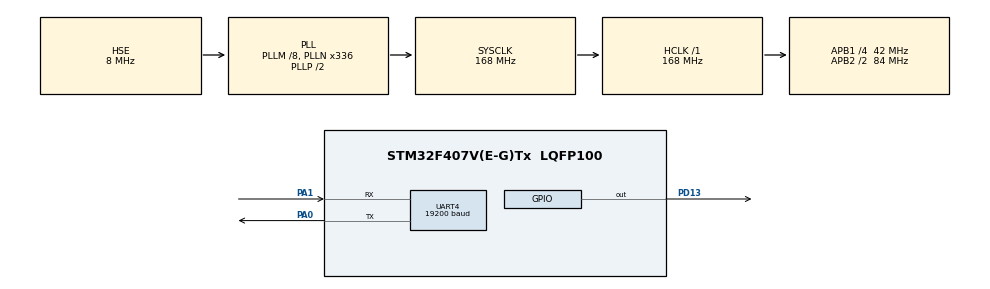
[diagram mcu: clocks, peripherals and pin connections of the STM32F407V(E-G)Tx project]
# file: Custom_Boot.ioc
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Mcu.Family=STM32F4
Mcu.Name=STM32F407V(E-G)Tx
Mcu.Package=LQFP100
NVIC.PriorityGroup=NVIC_PRIORITYGROUP_4
PA0-WKUP.Mode=Asynchronous
PA0-WKUP.Signal=UART4_TX
PA1.Mode=Asynchronous
PA1.Signal=UART4_RX
PD13.Signal=GPIO_Output
PH0-OSC_IN.Mode=HSE-External-Oscillator
PH0-OSC_IN.Signal=RCC_OSC_IN
PH1-OSC_OUT.Mode=HSE-External-Oscillator
PH1-OSC_OUT.Signal=RCC_OSC_OUT
ProjectManager.HeapSize=0x200
ProjectManager.StackSize=0x400
ProjectManager.TargetToolchain=STM32CubeIDE
RCC.48MHZClocksFreq_Value=84000000
RCC.AHBFreq_Value=168000000
RCC.APB1CLKDivider=RCC_HCLK_DIV4
RCC.APB1Freq_Value=42000000
RCC.APB1TimFreq_Value=84000000
RCC.APB2CLKDivider=RCC_HCLK_DIV2
RCC.APB2Freq_Value=84000000
RCC.APB2TimFreq_Value=168000000
RCC.CortexFreq_Value=168000000
RCC.HCLKFreq_Value=168000000
RCC.HSE_VALUE=8000000
RCC.HSI_VALUE=16000000
RCC.LSE_VALUE=32768
RCC.PLLM=8
RCC.PLLN=336
RCC.PLLSourceVirtual=RCC_PLLSOURCE_HSE
RCC.SYSCLKFreq_VALUE=168000000
RCC.SYSCLKSource=RCC_SYSCLKSOURCE_PLLCLK
RCC.VCOOutputFreq_Value=336000000
UART4.BaudRate=19200
UART4.VirtualMode=Asynchronous
board=custom

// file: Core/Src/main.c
/* USER CODE BEGIN Header */
/**
  ******************************************************************************
  * @file           : main.c
  * @brief          : Main program body
  ******************************************************************************
  * @attention
  *
  * Copyright (c) 2026 STMicroelectronics.
  * All rights reserved.
  *
  * This software is licensed under terms that can be found in the LICENSE file
  * in the root directory of this software component.
  * If no LICENSE file comes with this software, it is provided AS-IS.
  *
  ******************************************************************************
  */
/* USER CODE END Header */
#include "main.h"

/* USER CODE BEGIN Includes */
#include "bl_jump.h"
#include "bl_ota.h"
#include "ota_image.h"
/* USER CODE END Includes */

UART_HandleTypeDef huart4;

void SystemClock_Config(void);
static void MX_GPIO_Init(void);
static void MX_UART4_Init(void);

/* USER CODE BEGIN 0 */

static uint32_t mem_base = 0;  // used with external or dual flash
static uint32_t mem_cursor = 0;
static uint32_t ota_image_total_size = 16;  // expected OTA Header size

void ota_mem_set_total_size(uint32_t size)
{
    ota_image_total_size = size;
}

int ota_read_mem(uint8_t *buf, uint32_t len)
{
    if (mem_cursor + len > ota_image_total_size)
        return -1;

    memcpy(buf, &ota_image_bin[mem_base + mem_cursor], len);  // this function should be replaced accordingly

    mem_cursor += len;
    return 0;
}

/* USER CODE END 0 */

int main(void)
{

  /* MCU Configuration--------------------------------------------------------*/

  /* Reset of all peripherals, Initializes the Flash interface and the Systick. */
  HAL_Init();

  /* Configure the system clock */
  SystemClock_Config();

  /* Initialize all configured peripherals */
  MX_GPIO_Init();
  MX_UART4_Init();
  /* USER CODE BEGIN 2 */
  HAL_Delay(100);
  RCC->AHB1ENR |= RCC_AHB1ENR_GPIODEN;          // Active l'horloge de GPIOD
  GPIOD->MODER = (GPIOD->MODER & ~(3U << (13*2))) | (1U << (13*2)); // PD13 en sortie
  GPIOD->ODR |= (1U << 13);

  // TEST FLASH//

  // TEST FLASH//

  HAL_UART_Transmit(&huart4, (uint8_t *)"Inside Bootloader!!\r\n", 21, 100);

  if (check_ota_request() != 0)//check_ota_request() == 0
  {
	  HAL_UART_Transmit(&huart4, (uint8_t *)"Performing OTA...\n", 18, 100);

	  ota_stream_t stream =
	  {
	      .read = ota_read_mem,
	      .set_total_size = ota_mem_set_total_size
	  };

	  bl_ota_ctx_t ctx;
	 if (bl_ota_run(&ctx, &stream) != 0)
	 {
		 HAL_UART_Transmit(&huart4, (uint8_t *)"OTA Failed...\n", 14, 100);
		  while (1)
		  {
			  HAL_GPIO_TogglePin(GPIOD, GPIO_PIN_12);
			  HAL_Delay(250);
		  }
	 }
	 else {
		 HAL_UART_Transmit(&huart4, (uint8_t *)"OTA Flashed Successfully, Jumping to app...\n", 44, 100);
	 }

  }
  int err = bootloader_is_app_valid();
  if (err != 0)
  {
	  HAL_UART_Transmit(&huart4, (uint8_t *)"Failed to Jump!! ", 17, 100);
	  switch (err){
	  case 1:
		  HAL_UART_Transmit(&huart4, (uint8_t *)"MAGIC ERROR!!\r\n", 15, 100);
		  break;

	  case 2:
		  HAL_UART_Transmit(&huart4, (uint8_t *)"RESET ERROR!!\r\n", 15, 100);
		  break;

	  case 3:
		  HAL_UART_Transmit(&huart4, (uint8_t *)"SIZE ERROR!!\r\n", 14, 100);
		  break;

	  case 4:
		  HAL_UART_Transmit(&huart4, (uint8_t *)"CRC ERROR!!\r\n", 13, 100);
		  break;

	  default:
		  HAL_UART_Transmit(&huart4, (uint8_t *)"ERROR!!\r\n", 9, 100);
		  break;
	  }
  }

  JumpToApplication(); // Jump to the application
  /* USER CODE END 2 */

  /* Infinite loop */
  while (1)
  {

  }
}

void SystemClock_Config(void)
{
  RCC_OscInitTypeDef RCC_OscInitStruct = {0};
  RCC_ClkInitTypeDef RCC_ClkInitStruct = {0};

  /** Configure the main internal regulator output voltage
  */
  __HAL_RCC_PWR_CLK_ENABLE();
  __HAL_PWR_VOLTAGESCALING_CONFIG(PWR_REGULATOR_VOLTAGE_SCALE1);

  /** Initializes the RCC Oscillators according to the specified parameters
  * in the RCC_OscInitTypeDef structure.
  */
  RCC_OscInitStruct.OscillatorType = RCC_OSCILLATORTYPE_HSE;
  RCC_OscInitStruct.HSEState = RCC_HSE_ON;
  RCC_OscInitStruct.PLL.PLLState = RCC_PLL_ON;
  RCC_OscInitStruct.PLL.PLLSource = RCC_PLLSOURCE_HSE;
  RCC_OscInitStruct.PLL.PLLM = 8;
  RCC_OscInitStruct.PLL.PLLN = 336;
  RCC_OscInitStruct.PLL.PLLP = RCC_PLLP_DIV2;
  RCC_OscInitStruct.PLL.PLLQ = 4;
  if (HAL_RCC_OscConfig(&RCC_OscInitStruct) != HAL_OK)
  {
    Error_Handler();
  }

  /** Initializes the CPU, AHB and APB buses clocks
  */
  RCC_ClkInitStruct.ClockType = RCC_CLOCKTYPE_HCLK|RCC_CLOCKTYPE_SYSCLK
                              |RCC_CLOCKTYPE_PCLK1|RCC_CLOCKTYPE_PCLK2;
  RCC_ClkInitStruct.SYSCLKSource = RCC_SYSCLKSOURCE_PLLCLK;
  RCC_ClkInitStruct.AHBCLKDivider = RCC_SYSCLK_DIV1;
  RCC_ClkInitStruct.APB1CLKDivider = RCC_HCLK_DIV4;
  RCC_ClkInitStruct.APB2CLKDivider = RCC_HCLK_DIV2;

  if (HAL_RCC_ClockConfig(&RCC_ClkInitStruct, FLASH_LATENCY_5) != HAL_OK)
  {
    Error_Handler();
  }
}

static void MX_UART4_Init(void)
{

  huart4.Instance = UART4;
  huart4.Init.BaudRate = 19200;
  huart4.Init.WordLength = UART_WORDLENGTH_8B;
  huart4.Init.StopBits = UART_STOPBITS_1;
  huart4.Init.Parity = UART_PARITY_NONE;
  huart4.Init.Mode = UART_MODE_TX_RX;
  huart4.Init.HwFlowCtl = UART_HWCONTROL_NONE;
  huart4.Init.OverSampling = UART_OVERSAMPLING_16;
  if (HAL_UART_Init(&huart4) != HAL_OK)
  {
    Error_Handler();
  }

}

static void MX_GPIO_Init(void)
{
  GPIO_InitTypeDef GPIO_InitStruct = {0};

  /* GPIO Ports Clock Enable */
  __HAL_RCC_GPIOH_CLK_ENABLE();
  __HAL_RCC_GPIOA_CLK_ENABLE();
  __HAL_RCC_GPIOD_CLK_ENABLE();

  /*Configure GPIO pin Output Level */
  HAL_GPIO_WritePin(GPIOD, GPIO_PIN_13, GPIO_PIN_RESET);

  /*Configure GPIO pin : PD13 */
  GPIO_InitStruct.Pin = GPIO_PIN_13;
  GPIO_InitStruct.Mode = GPIO_MODE_OUTPUT_PP;
  GPIO_InitStruct.Pull = GPIO_NOPULL;
  GPIO_InitStruct.Speed = GPIO_SPEED_FREQ_LOW;
  HAL_GPIO_Init(GPIOD, &GPIO_InitStruct);

  /* USER CODE BEGIN MX_GPIO_Init_2 */
  /* UART4 TX PA0 */
  GPIO_InitStruct.Pin = GPIO_PIN_0;
  GPIO_InitStruct.Mode = GPIO_MODE_AF_PP;
  GPIO_InitStruct.Pull = GPIO_NOPULL;
  GPIO_InitStruct.Speed = GPIO_SPEED_FREQ_VERY_HIGH;
  GPIO_InitStruct.Alternate = GPIO_AF8_UART4;
  HAL_GPIO_Init(GPIOA, &GPIO_InitStruct);

  /* UART4 RX PA1 */
  GPIO_InitStruct.Pin = GPIO_PIN_1;
  GPIO_InitStruct.Alternate = GPIO_AF8_UART4;
  HAL_GPIO_Init(GPIOA, &GPIO_InitStruct);

  /* USER CODE END MX_GPIO_Init_2 */
}

void Error_Handler(void)
{
  __disable_irq();
  while (1)
  {
  }
}
